# AT32A423xx_v2 register map
Vendor: Keil; Series: AT32A423; File version: 1.0
CPU: CM4 r0p1, little endian, no MPU, FPU, 4 interrupt priority bits
Registers are 32-bit, read-write, reset 0x0 unless marked. A register's access mark holds for its fields unless they carry their own. Offsets are from the block's base; [hi:lo] are bit positions; {n}, {i} and the like mark numbered series; 'fields as' and 'values as' point back to an identical list.

## DEBUG — Debug support
Base 0xE0042000
0x00 IDCODE ro — DEBUG IDCODE
  [31:0] PID — Product ID
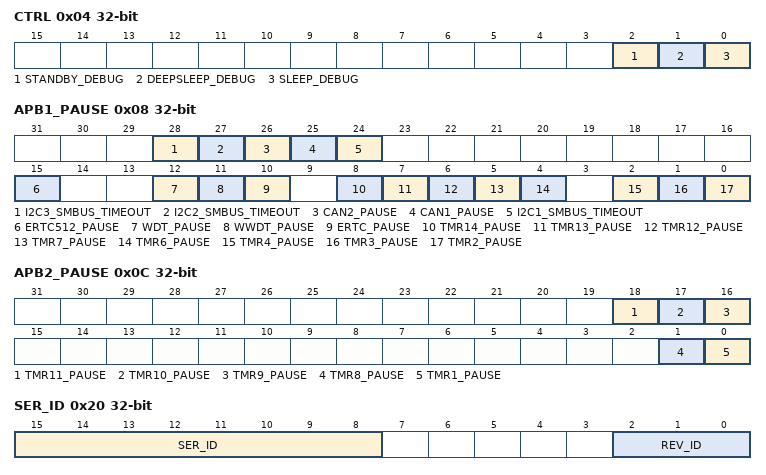
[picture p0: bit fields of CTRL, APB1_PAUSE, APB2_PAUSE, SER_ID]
0x04 CTRL — DEBUG CTRL
  [2] STANDBY_DEBUG, [1] DEEPSLEEP_DEBUG, [0] SLEEP_DEBUG
0x08 APB1_PAUSE — DEBUG APB1 PAUSE
  [28] I2C3_SMBUS_TIMEOUT, [27] I2C2_SMBUS_TIMEOUT, [26] CAN2_PAUSE, [25] CAN1_PAUSE, [24] I2C1_SMBUS_TIMEOUT, [15] ERTC512_PAUSE, [12] WDT_PAUSE, [11] WWDT_PAUSE, [10] ERTC_PAUSE, [8] TMR14_PAUSE, [7] TMR13_PAUSE, [6] TMR12_PAUSE, [5] TMR7_PAUSE, [4] TMR6_PAUSE, [2] TMR4_PAUSE, [1] TMR3_PAUSE, [0] TMR2_PAUSE
0x0C APB2_PAUSE — DEBUG APB2 PAUSE
  [18] TMR11_PAUSE, [17] TMR10_PAUSE, [16] TMR9_PAUSE, [1] TMR8_PAUSE, [0] TMR1_PAUSE
0x20 SER_ID ro — SERIES ID
  [15:8] SER_ID — series ID
  [2:0] REV_ID — version ID

## CRC — CRC calculation unit
Base 0x40023000
0x00 DT reset 0xFFFFFFFF — Data register
  [31:0] DT — Data Register
0x04 CDT — Common data register
  [0] CDT — Common Data
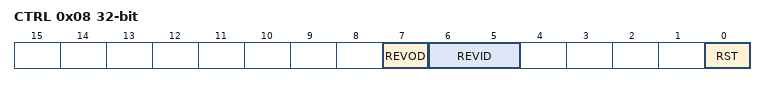
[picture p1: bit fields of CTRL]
0x08 CTRL — Control register
  [7] REVOD — Reverse output data
  [6:5] REVID — Reverse input data
  [0] RST — Reset bit
0x10 IDT reset 0xFFFFFFFF — Initial data register
  [31:0] IDT — Initial Data

## NVIC — Nested Vectored Interrupt Controller
Base 0xE000E000
0x04 ICTR ro — Interrupt Controller Type Register
  [3:0] INTLINESNUM — Total number of interrupt lines in groups
0x100 ISER0 — Interrupt Set-Enable Register
  [31:0] SETENA
0x104 ISER1 — Interrupt Set-Enable Register
  [31:0] SETENA
0x180 ICER0 — Interrupt Clear-Enable Register
  [31:0] CLRENA
0x184 ICER1 — Interrupt Clear-Enable Register
  [31:0] CLRENA
0x200 ISPR0 — Interrupt Set-Pending Register
  [31:0] SETPEND
0x204 ISPR1 — Interrupt Set-Pending Register
  [31:0] SETPEND
0x280 ICPR0 — Interrupt Clear-Pending Register
  [31:0] CLRPEND
0x284 ICPR1 — Interrupt Clear-Pending Register
  [31:0] CLRPEND
0x300 IABR0 ro — Interrupt Active Bit Register
  [31:0] ACTIVE
0x304 IABR1 ro — Interrupt Active Bit Register
  [31:0] ACTIVE
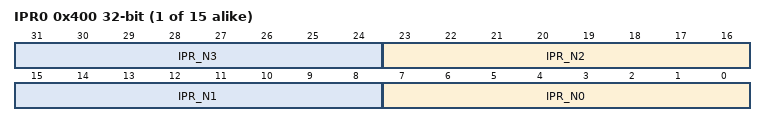
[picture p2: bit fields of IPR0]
{0x400+4i} IPR{i} (i=0..14) — Interrupt Priority Register
  [8n+7:8n] IPR_N{n} (n=0..3)
0xF00 STIR wo — Software Triggered Interrupt Register
  [8:0] INTID — interrupt to be triggered

## USB_OTGFS_HOST — USB on the go full speed
Base 0x50000400
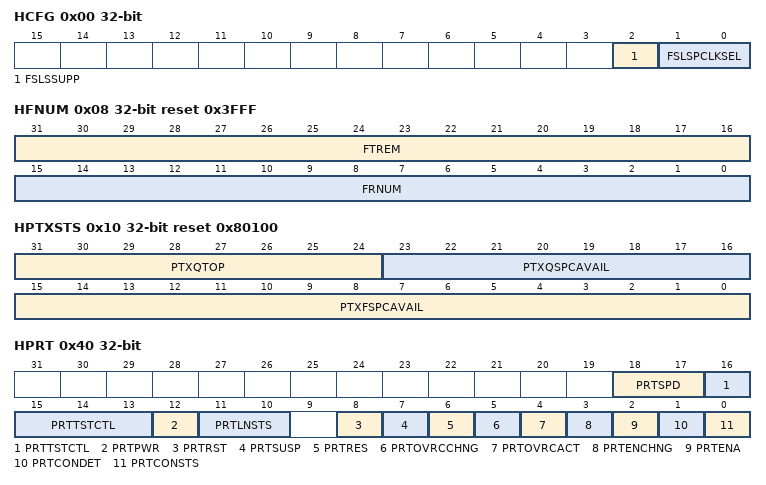
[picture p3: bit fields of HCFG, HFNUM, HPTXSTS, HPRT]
0x00 HCFG — OTGFS host configuration register (OTGFS_HCFG)
  [2] FSLSSUPP ro — FS- and LS-only support
  [1:0] FSLSPCLKSEL — FS/LS PHY clock select
0x04 HFIR reset 0xEA60 — OTGFS Host frame interval register
  [15:0] FRINT — Frame interval
0x08 HFNUM ro reset 0x3FFF — OTGFS host frame number/frame time remaining register (OTGFS_HFNUM)
  [31:16] FTREM — Frame time remaining
  [15:0] FRNUM — Frame number
0x10 HPTXSTS reset 0x80100 — OTGFS_Host periodic transmit FIFO/queue status register (OTGFS_HPTXSTS)
  [31:24] PTXQTOP ro — Top of the periodic transmit request queue
  [23:16] PTXQSPCAVAIL ro — Periodic transmit request queue space available
  [15:0] PTXFSPCAVAIL — Periodic transmit data FIFO space available
0x14 HAINT ro — OTGFS Host all channels interrupt register
  [15:0] HAINT — Channel interrupts
0x18 HAINTMSK — OTGFS host all channels interrupt mask register
  [15:0] HAINTMSK — Channel interrupt mask
0x40 HPRT — OTGFS host port control and status register (OTGFS_HPRT)
  [18:17] PRTSPD ro — Port speed
  [16:13] PRTTSTCTL — Port test control
  [12] PRTPWR — Port power
  [11:10] PRTLNSTS ro — Port line status
  [8] PRTRST — Port reset
  [7] PRTSUSP — Port suspend
  [6] PRTRES — Port resume
  [5] PRTOVRCCHNG — Port overcurrent change
  [4] PRTOVRCACT ro — Port overcurrent active
  [3] PRTENCHNG — Port enable/disable change
  [2] PRTENA — Port enable
  [1] PRTCONDET — Port connect detected
  [0] PRTCONSTS ro — Port connect status
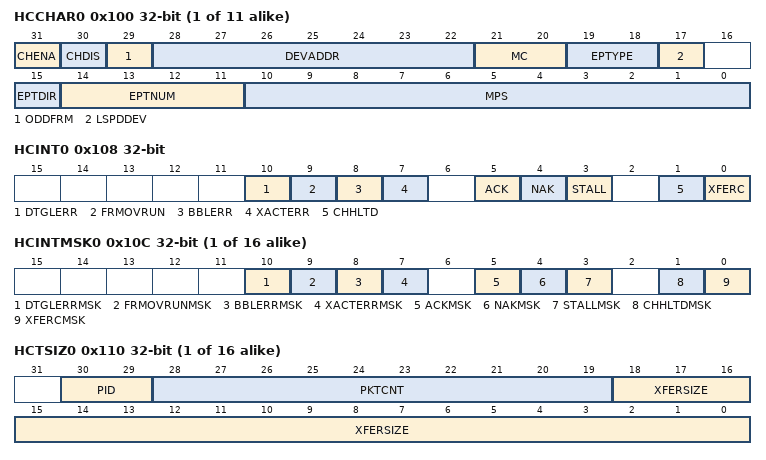
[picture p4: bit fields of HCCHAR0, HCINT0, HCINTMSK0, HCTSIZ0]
{0x100+0x20*i} HCCHAR{i} (i=0..10) — OTGFS host channel-{i} characteristics register (OTGFS_HCCHAR{i})
  [31] CHENA — Channel enable
  [30] CHDIS — Channel disable
  [29] ODDFRM — Odd frame
  [28:22] DEVADDR — Device address
  [21:20] MC — Multicount
  [19:18] EPTYPE — Endpoint type
  [17] LSPDDEV — Low-speed device
  [15] EPTDIR — Endpoint direction
  [14:11] EPTNUM — Endpoint number
  [10:0] MPS — Maximum packet size
0x108 HCINT0 — OTGFS host channel-0 interrupt register (OTGFS_HCINT0)
  [10] DTGLERR — Data toggle error
  [9] FRMOVRUN — Frame overrun
  [8] BBLERR — Babble error
  [7] XACTERR — Transaction error
  [5] ACK — ACK response received/transmitted interrupt
  [4] NAK — NAK response received interrupt
  [3] STALL — STALL response received interrupt
  [1] CHHLTD — Channel halted
  [0] XFERC — Transfer completed
{0x10C+0x20*i} HCINTMSK{i} (i=0..15) — OTGFS host channel-{i} mask register (OTGFS_HCINTMSK{i})
  [10] DTGLERRMSK — Data toggle error mask
  [9] FRMOVRUNMSK — Frame overrun mask
  [8] BBLERRMSK — Babble error mask
  [7] XACTERRMSK — Transaction error mask
  [5] ACKMSK — ACK response received/transmitted interrupt mask
  [4] NAKMSK — NAK response received interrupt mask
  [3] STALLMSK — STALL response received interrupt mask
  [1] CHHLTDMSK — Channel halted mask
  [0] XFERCMSK — Transfer completed mask
{0x110+0x20*i} HCTSIZ{i} (i=0..15) — OTGFS host channel-{i} transfer size register
  [30:29] PID
  [28:19] PKTCNT — Packet count
  [18:0] XFERSIZE — Transfer size
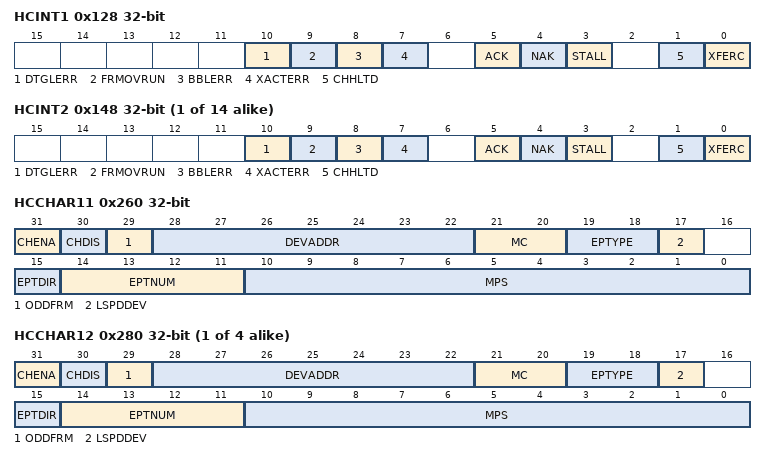
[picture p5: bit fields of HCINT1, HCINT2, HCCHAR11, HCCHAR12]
0x128 HCINT1 — OTG_FS host channel-1 interrupt register (OTG_FS_HCINT1)
  fields as HCINT0
{0x108+0x20*i} HCINT{i} (i=2..15) — OTGFS host channel-{i} interrupt register (OTGFS_HCINT{i})
  fields as HCINT0
0x260 HCCHAR11 — OTGFS host channel-7 characteristics register (OTGFS_HCCHAR11)
  fields as HCCHAR0
{0x100+0x20*i} HCCHAR{i} (i=12..15) — OTGFS host channel-{i} characteristics register (OTGFS_HCCHAR{i})
  fields as HCCHAR0

## Notices in the file
Copyright (C) 2012-2014 ARM Limited. All rights reserved.
Purpose: System Viewer Description (SVD) Example (Schema Version 1.1)
This is a description of a none-existent and incomplete device
for demonstration purposes only.
Redistribution and use in source and binary forms, with or without
modification, are permitted provided that the following conditions are met:
- Redistributions of source code must retain the above copyright
notice, this list of conditions and the following disclaimer.
- Redistributions in binary form must reproduce the above copyright
notice, this list of conditions and the following disclaimer in the
documentation and/or other materials provided with the distribution.
- Neither the name of ARM nor the names of its contributors may be used
to endorse or promote products derived from this software without
specific prior written permission.
THIS SOFTWARE IS PROVIDED BY THE COPYRIGHT HOLDERS AND CONTRIBUTORS "AS IS"
AND ANY EXPRESS OR IMPLIED WARRANTIES, INCLUDING, BUT NOT LIMITED TO, THE
IMPLIED WARRANTIES OF MERCHANTABILITY AND FITNESS FOR A PARTICULAR PURPOSE
ARE DISCLAIMED. IN NO EVENT SHALL COPYRIGHT HOLDERS AND CONTRIBUTORS BE
LIABLE FOR ANY DIRECT, INDIRECT, INCIDENTAL, SPECIAL, EXEMPLARY, OR
CONSEQUENTIAL DAMAGES (INCLUDING, BUT NOT LIMITED TO, PROCUREMENT OF
SUBSTITUTE GOODS OR SERVICES; LOSS OF USE, DATA, OR PROFITS; OR BUSINESS
INTERRUPTION) HOWEVER CAUSED AND ON ANY THEORY OF LIABILITY, WHETHER IN
CONTRACT, STRICT LIABILITY, OR TORT (INCLUDING NEGLIGENCE OR OTHERWISE)
ARISING IN ANY WAY OUT OF THE USE OF THIS SOFTWARE, EVEN IF ADVISED OF THE
POSSIBILITY OF SUCH DAMAGE.
